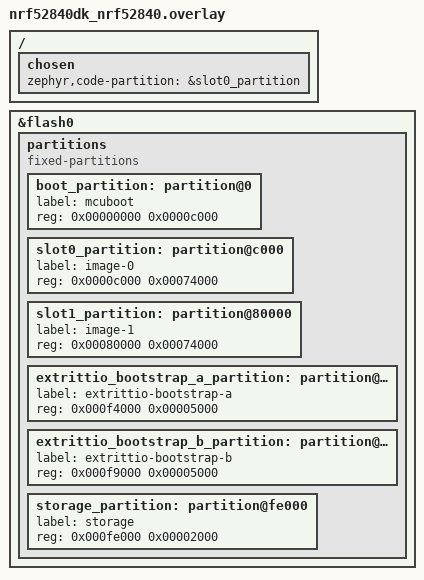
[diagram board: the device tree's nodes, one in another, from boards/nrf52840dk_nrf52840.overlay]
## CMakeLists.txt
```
# Copyright (c) 2026 Extrittio contributors
# SPDX-License-Identifier: Apache-2.0

cmake_minimum_required(VERSION 3.20.0)

list(APPEND ZEPHYR_EXTRA_MODULES
  "${CMAKE_CURRENT_LIST_DIR}/../c/sdk-c"
)
find_package(Zephyr REQUIRED HINTS $ENV{ZEPHYR_BASE})
project(extrittio_zephyr)

# zenoh-pico 1.9.0 contains an mbedTLS transport but its upstream Zephyr glue
# does not expose it. Compile that existing port into the application and make
# the feature visible consistently to both the library and application sources.
zephyr_compile_definitions(ZENOH_GENERIC)
zephyr_include_directories(include)
target_include_directories(zephyr_interface BEFORE INTERFACE
  ${CMAKE_CURRENT_LIST_DIR}/include
)

target_sources(app PRIVATE
  src/main.c
  src/identity.c
  src/provisioning_store.c
  src/ble_provisioning.c
  src/network.c
  src/client.c
  src/ota.c
  src/zenoh_tls.c
  ${ZEPHYR_ZENOH_PICO_MODULE_DIR}/src/runtime/background_executor.c
  ${ZEPHYR_ZENOH_PICO_MODULE_DIR}/src/runtime/executor.c
)

target_include_directories(app PRIVATE
  include
  ../c/sdk-c/include
)
```

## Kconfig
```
# Copyright (c) 2026 Extrittio contributors
# SPDX-License-Identifier: Apache-2.0

menu "Extrittio Zephyr client"

config EXTRITTIO_FACTORY_DEVICE_ID
	string "Factory device identity"
	default ""
	help
	  Stable factory identity presented over BLE and checked against the
	  bootstrap package. Production builds should derive this from protected
	  manufacturing data instead of using this development setting.

config EXTRITTIO_MODEL
	string "Device model"
	default "zephyr-device"

config EXTRITTIO_FIRMWARE_VERSION
	string "Firmware version"
	default "0.1.0"

config EXTRITTIO_PROVISIONING_WINDOW_SECONDS
	int "BLE provisioning window after boot"
	default 300
	range 30 3600
	help
	  A provisioned device advertises the provisioning service after boot only
	  when the board's sw0 button is held. An unprovisioned device always opens
	  this bounded window.

config EXTRITTIO_BOOTSTRAP_BUFFER_SIZE
	int "Bootstrap validation buffer size"
	default 16384
	range 4096 65536

config EXTRITTIO_ZENOH_RETRY_SECONDS
	int "Zenoh reconnect delay"
	default 5
	range 1 300

config EXTRITTIO_OTA_DOWNLOAD_BUFFER_SIZE
	int "OTA HTTP receive buffer"
	default 1024
	range 512 8192

endmenu

source "Kconfig.zephyr"
```

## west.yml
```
manifest:
  version: "1.2"

  projects:
    - name: zephyr
      url: https://github.com/zephyrproject-rtos/zephyr.git
      revision: 1f6485eca25431b5ff27ce9a754218c9e559bbbb # v4.4.1
      import: true
    - name: zenoh-pico
      url: https://github.com/eclipse-zenoh/zenoh-pico.git
      revision: e83d39b4415f6897e8d6c3b3b651ca88a05f4a17 # v1.9.0
      path: modules/lib/zenoh-pico
    - name: cjson
      url: https://github.com/DaveGamble/cJSON.git
      revision: acc76239bee01d8e9c858ae2cab296704e52d916 # v1.7.18
      path: modules/lib/cjson

  self:
    path: extrittio
```

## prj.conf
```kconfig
CONFIG_MAIN_STACK_SIZE=6144
CONFIG_SYSTEM_WORKQUEUE_STACK_SIZE=4096
CONFIG_HEAP_MEM_POOL_SIZE=98304

CONFIG_GPIO=y
CONFIG_FLASH=y
CONFIG_FLASH_MAP=y
CONFIG_STREAM_FLASH=y
CONFIG_SETTINGS=y
CONFIG_SETTINGS_NVS=y
CONFIG_NVS=y
CONFIG_MPU_ALLOW_FLASH_WRITE=y

CONFIG_BT=y
CONFIG_BT_PERIPHERAL=y
CONFIG_BT_SMP=y
CONFIG_BT_BONDABLE=y
CONFIG_BT_SETTINGS=y
CONFIG_BT_GATT_DYNAMIC_DB=y
CONFIG_BT_DEVICE_NAME="Extrittio"
CONFIG_BT_DEVICE_APPEARANCE=0
CONFIG_BT_BUF_ACL_RX_SIZE=251
CONFIG_BT_BUF_ACL_TX_SIZE=251
CONFIG_BT_L2CAP_TX_MTU=247
CONFIG_BT_CTLR_DATA_LENGTH_MAX=251

CONFIG_NETWORKING=y
CONFIG_NET_IPV6=y
CONFIG_NET_TCP=y
CONFIG_NET_SOCKETS=y
CONFIG_OPENTHREAD=y
CONFIG_OPENTHREAD_SHELL=n
CONFIG_OPENTHREAD_MTD=y
CONFIG_OPENTHREAD_FTD=n
CONFIG_OPENTHREAD_JOINER=n
CONFIG_OPENTHREAD_MANUAL_START=y
CONFIG_OPENTHREAD_THREAD_VERSION_1_3=y

CONFIG_MBEDTLS=y
CONFIG_MBEDTLS_ENABLE_HEAP=y
CONFIG_MBEDTLS_HEAP_SIZE=65536
CONFIG_MBEDTLS_ENTROPY_C=y
CONFIG_MBEDTLS_HMAC_DRBG_C=y
CONFIG_MBEDTLS_MD_C=y
CONFIG_PSA_WANT_ALG_SHA_256=y
CONFIG_MBEDTLS_BASE64_C=y
CONFIG_MBEDTLS_PEM_PARSE_C=y
CONFIG_MBEDTLS_PK_PARSE_C=y
CONFIG_MBEDTLS_X509_CRT_PARSE_C=y
CONFIG_MBEDTLS_SSL_PROTO_TLS1_2=y
CONFIG_MBEDTLS_SSL_SERVER_NAME_INDICATION=y
CONFIG_MBEDTLS_KEY_EXCHANGE_ALL_ENABLED=y

CONFIG_BOOTLOADER_MCUBOOT=y
CONFIG_IMG_MANAGER=y
CONFIG_MCUBOOT_IMG_MANAGER=y
CONFIG_IMG_ERASE_PROGRESSIVELY=y
CONFIG_HTTP_CLIENT=y
CONFIG_DNS_RESOLVER=y

CONFIG_NANOPB=y
CONFIG_EXTRITTIO_SDK_C=y
CONFIG_ZENOH_PICO=y
CONFIG_ZENOH_PICO_MULTI_THREAD=y
CONFIG_ZENOH_PICO_PUBLICATION=y
CONFIG_ZENOH_PICO_SUBSCRIPTION=y
CONFIG_ZENOH_PICO_LINK_TCP=y
CONFIG_ZENOH_PICO_LINK_TLS=y
CONFIG_ZENOH_PICO_QUERY=n
CONFIG_ZENOH_PICO_QUERYABLE=n
CONFIG_ZENOH_PICO_SCOUTING=n

CONFIG_LOG=y
CONFIG_LOG_MODE_DEFERRED=y
CONFIG_LOG_DEFAULT_LEVEL=3
```

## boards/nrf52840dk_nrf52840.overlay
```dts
/ {
	chosen {
		zephyr,code-partition = &slot0_partition;
	};
};

&flash0 {
	/delete-node/ partitions;

	partitions {
		compatible = "fixed-partitions";
		#address-cells = <1>;
		#size-cells = <1>;

		boot_partition: partition@0 {
			label = "mcuboot";
			reg = <0x00000000 0x0000c000>;
		};
		slot0_partition: partition@c000 {
			label = "image-0";
			reg = <0x0000c000 0x00074000>;
		};
		slot1_partition: partition@80000 {
			label = "image-1";
			reg = <0x00080000 0x00074000>;
		};
		extrittio_bootstrap_a_partition: partition@f4000 {
			label = "extrittio-bootstrap-a";
			reg = <0x000f4000 0x00005000>;
		};
		extrittio_bootstrap_b_partition: partition@f9000 {
			label = "extrittio-bootstrap-b";
			reg = <0x000f9000 0x00005000>;
		};
		storage_partition: partition@fe000 {
			label = "storage";
			reg = <0x000fe000 0x00002000>;
		};
	};
};
```

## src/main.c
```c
#include <errno.h>
#include <stdbool.h>

#include <zephyr/device.h>
#include <zephyr/devicetree.h>
#include <zephyr/drivers/gpio.h>
#include <zephyr/kernel.h>
#include <zephyr/logging/log.h>
#include <zephyr/dfu/mcuboot.h>

#include <extrittio/bootstrap.h>

#include "extrittio_zephyr/ble_provisioning.h"
#include "extrittio_zephyr/client.h"
#include "extrittio_zephyr/identity.h"
#include "extrittio_zephyr/network.h"
#include "extrittio_zephyr/ota.h"
#include "extrittio_zephyr/provisioning_store.h"

LOG_MODULE_REGISTER(extrittio_main, CONFIG_LOG_DEFAULT_LEVEL);

#if DT_NODE_HAS_STATUS(DT_ALIAS(sw0), okay)
static const struct gpio_dt_spec provisioning_button =
    GPIO_DT_SPEC_GET(DT_ALIAS(sw0), gpios);
#endif

static bool provisioning_button_pressed(void) {
#if DT_NODE_HAS_STATUS(DT_ALIAS(sw0), okay)
    if (!gpio_is_ready_dt(&provisioning_button) ||
        gpio_pin_configure_dt(&provisioning_button, GPIO_INPUT) != 0) {
        return false;
    }
    return gpio_pin_get_dt(&provisioning_button) > 0;
#else
    return false;
#endif
}

static void default_command(const extrittio_command_t *command,
                            void *user_data) {
    ARG_UNUSED(user_data);
    LOG_WRN("No application handler for command %s", command->command);
}

static void default_shadow(const char *device_id, const char *delta_json,
                           int64_t version, void *user_data) {
    ARG_UNUSED(device_id);
    LOG_INF("Received shadow delta version %lld", version);
    extrittio_ota_payload_t update;
    if (extrittio_ota_parse_from_delta(delta_json, &update)) {
        int result = extrittio_zephyr_ota_request(user_data, &update);
        if (result != 0 && result != -EBUSY) {
            LOG_ERR("Could not schedule firmware update: %d", result);
        }
    }
}

int main(void) {
    if (extrittio_identity_init() != 0 ||
        extrittio_provisioning_store_init() != 0 ||
        extrittio_ble_provisioning_init() != 0) {
        LOG_ERR("Extrittio platform initialization failed");
        return -EIO;
    }
    (void)boot_write_img_confirmed();

    bool provisioned = extrittio_provisioning_store_has_bootstrap();
    bool physical_reprovision = provisioned && provisioning_button_pressed();
    if (!provisioned || physical_reprovision) {
        if (extrittio_ble_provisioning_start(physical_reprovision) != 0) {
            LOG_ERR("Could not open BLE provisioning window");
            return -EIO;
        }
        k_sleep(K_SECONDS(CONFIG_EXTRITTIO_PROVISIONING_WINDOW_SECONDS));
        (void)extrittio_ble_provisioning_stop();
        if (!provisioned) {
            LOG_WRN("Provisioning window expired; reboot to try again");
            return -ETIMEDOUT;
        }
    }

    extrittio_bootstrap_t *bootstrap = k_malloc(sizeof(*bootstrap));
    if (bootstrap == NULL) {
        return -ENOMEM;
    }
    int result = extrittio_provisioning_store_load(bootstrap);
    if (result != 0) {
        LOG_ERR("Stored bootstrap is invalid: %d", result);
        k_free(bootstrap);
        return result;
    }
    result = extrittio_network_start(&bootstrap->network);
    if (result != 0) {
        LOG_ERR("Network start failed: %d", result);
        extrittio_bootstrap_clear(bootstrap);
        k_free(bootstrap);
        return result;
    }

    const extrittio_zephyr_client_callbacks_t callbacks = {
        .command = default_command,
        .shadow_delta = default_shadow,
        .user_data = bootstrap,
    };
    result = extrittio_zephyr_client_run(bootstrap, &callbacks);
    extrittio_bootstrap_clear(bootstrap);
    k_free(bootstrap);
    return result;
}
```

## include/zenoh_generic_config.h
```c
#ifndef EXTRITTIO_ZENOH_GENERIC_CONFIG_H
#define EXTRITTIO_ZENOH_GENERIC_CONFIG_H

/* Feature profile for the pinned zenoh-pico 1.9.0 Zephyr client. */
#define Z_FRAG_MAX_SIZE 4096
#define Z_BATCH_UNICAST_SIZE 2048
#define Z_BATCH_MULTICAST_SIZE 2048
#define Z_CONFIG_SOCKET_TIMEOUT 100
#define Z_TRANSPORT_LEASE 10000
#define Z_TRANSPORT_LEASE_EXPIRE_FACTOR 3
#define Z_RUNTIME_MAX_TASKS 8
#define Z_TRANSPORT_ACCEPT_TIMEOUT 1000
#define Z_TRANSPORT_CONNECT_TIMEOUT 10000

#define Z_FEATURE_UNSTABLE_API 0
#define Z_FEATURE_CONNECTIVITY 0
#define Z_FEATURE_MULTI_THREAD 1
#define Z_FEATURE_PUBLICATION 1
#define Z_FEATURE_ADVANCED_PUBLICATION 0
#define Z_FEATURE_SUBSCRIPTION 1
#define Z_FEATURE_ADVANCED_SUBSCRIPTION 0
#define Z_FEATURE_QUERY 0
#define Z_FEATURE_QUERYABLE 0
#define Z_FEATURE_LIVELINESS 0
#define Z_FEATURE_RAWETH_TRANSPORT 0
#define Z_FEATURE_INTEREST 1
#define Z_FEATURE_LINK_TCP 1
#define Z_FEATURE_LINK_BLUETOOTH 0
#define Z_FEATURE_LINK_WS 0
#define Z_FEATURE_LINK_SERIAL 0
#define Z_FEATURE_LINK_SERIAL_USB 0
#define Z_FEATURE_LINK_TLS 1
#define Z_FEATURE_SCOUTING 0
#define Z_FEATURE_LINK_UDP_MULTICAST 0
#define Z_FEATURE_LINK_UDP_UNICAST 0
#define Z_FEATURE_MULTICAST_TRANSPORT 1
#define Z_FEATURE_UNICAST_TRANSPORT 1
#define Z_FEATURE_FRAGMENTATION 1
#define Z_FEATURE_ENCODING_VALUES 1
#define Z_FEATURE_TCP_NODELAY 1
#define Z_FEATURE_LOCAL_SUBSCRIBER 0
#define Z_FEATURE_LOCAL_QUERYABLE 0
#define Z_FEATURE_SESSION_CHECK 1
#define Z_FEATURE_BATCHING 1
#define Z_FEATURE_BATCH_TX_MUTEX 0
#define Z_FEATURE_BATCH_PEER_MUTEX 0
#define Z_FEATURE_MATCHING 1
#define Z_FEATURE_RX_CACHE 0
#define Z_FEATURE_UNICAST_PEER 0
#define Z_FEATURE_AUTO_RECONNECT 0
#define Z_FEATURE_MULTICAST_DECLARATIONS 0
#define Z_FEATURE_PERIODIC_TASKS 0
#define Z_FEATURE_ADMIN_SPACE 0

#endif
```

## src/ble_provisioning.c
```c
#include "extrittio_zephyr/ble_provisioning.h"

#include <errno.h>
#include <stdio.h>
#include <string.h>

#include <zephyr/bluetooth/bluetooth.h>
#include <zephyr/bluetooth/conn.h>
#include <zephyr/bluetooth/gatt.h>
#include <zephyr/bluetooth/uuid.h>
#include <zephyr/kernel.h>
#include <zephyr/logging/log.h>
#include <zephyr/settings/settings.h>
#include <zephyr/sys/reboot.h>

#include <extrittio/provisioning.h>

#include "extrittio_zephyr/identity.h"
#include "extrittio_zephyr/provisioning_store.h"

LOG_MODULE_REGISTER(extrittio_ble, CONFIG_LOG_DEFAULT_LEVEL);

#define EX_UUID(value) BT_UUID_128_ENCODE(value, 0x1a7c, 0x4a21, 0x9f25, 0xe6b17eb89c11)

static struct bt_uuid_128 service_uuid =
    BT_UUID_INIT_128(EX_UUID(0x9d8d0001));
static struct bt_uuid_128 device_id_uuid =
    BT_UUID_INIT_128(EX_UUID(0x9d8d0002));
static struct bt_uuid_128 model_uuid =
    BT_UUID_INIT_128(EX_UUID(0x9d8d0003));
static struct bt_uuid_128 firmware_uuid =
    BT_UUID_INIT_128(EX_UUID(0x9d8d0004));
static struct bt_uuid_128 transport_uuid =
    BT_UUID_INIT_128(EX_UUID(0x9d8d0005));
static struct bt_uuid_128 message_uuid =
    BT_UUID_INIT_128(EX_UUID(0x9d8d0006));
static struct bt_uuid_128 capabilities_uuid =
    BT_UUID_INIT_128(EX_UUID(0x9d8d0007));

static extrittio_provisioning_transfer_t transfer;
static bool provisioning_allowed;
static char capabilities[192];
static struct k_work_delayable reboot_work;

static ssize_t read_text(struct bt_conn *connection,
                         const struct bt_gatt_attr *attribute, void *buffer,
                         uint16_t length, uint16_t offset,
                         const char *value) {
    return bt_gatt_attr_read(connection, attribute, buffer, length, offset,
                             value, strlen(value));
}

static ssize_t read_device_id(struct bt_conn *connection,
                              const struct bt_gatt_attr *attribute,
                              void *buffer, uint16_t length, uint16_t offset) {
    return read_text(connection, attribute, buffer, length, offset,
                     extrittio_factory_device_id());
}

static ssize_t read_model(struct bt_conn *connection,
                          const struct bt_gatt_attr *attribute, void *buffer,
                          uint16_t length, uint16_t offset) {
    return read_text(connection, attribute, buffer, length, offset,
                     extrittio_device_model());
}

static ssize_t read_firmware(struct bt_conn *connection,
                             const struct bt_gatt_attr *attribute,
                             void *buffer, uint16_t length, uint16_t offset) {
    return read_text(connection, attribute, buffer, length, offset,
                     extrittio_firmware_version());
}

static ssize_t read_transport(struct bt_conn *connection,
                              const struct bt_gatt_attr *attribute,
                              void *buffer, uint16_t length, uint16_t offset) {
    return read_text(connection, attribute, buffer, length, offset,
                     "thread+zenoh-mtls");
}

static ssize_t read_capabilities(struct bt_conn *connection,
                                 const struct bt_gatt_attr *attribute,
                                 void *buffer, uint16_t length,
                                 uint16_t offset) {
    return read_text(connection, attribute, buffer, length, offset,
                     capabilities);
}

static void reboot_handler(struct k_work *work) {
    ARG_UNUSED(work);
    sys_reboot(SYS_REBOOT_COLD);
}

static ssize_t write_message(struct bt_conn *connection,
                             const struct bt_gatt_attr *attribute,
                             const void *buffer, uint16_t length,
                             uint16_t offset, uint8_t flags) {
    ARG_UNUSED(connection);
    ARG_UNUSED(attribute);
    ARG_UNUSED(flags);
    if (!provisioning_allowed || offset != 0U) {
        return BT_GATT_ERR(BT_ATT_ERR_WRITE_NOT_PERMITTED);
    }

    extrittio_provisioning_result_t result =
        extrittio_provisioning_transfer_handle(
            &transfer, buffer, length,
            extrittio_provisioning_store_callbacks(), NULL);
    if (result != EXTRITTIO_PROVISIONING_OK) {
        LOG_WRN("Rejected provisioning frame: %d", result);
        return BT_GATT_ERR(BT_ATT_ERR_VALUE_NOT_ALLOWED);
    }
    if (length >= 4U && ((const uint8_t *)buffer)[3] ==
                            EXTRITTIO_PROVISIONING_COMMIT_OPCODE) {
        provisioning_allowed = false;
        (void)k_work_reschedule(&reboot_work, K_SECONDS(1));
    }
    return length;
}

BT_GATT_SERVICE_DEFINE(
    extrittio_service,
    BT_GATT_PRIMARY_SERVICE(&service_uuid),
    BT_GATT_CHARACTERISTIC(&device_id_uuid.uuid, BT_GATT_CHRC_READ,
                           BT_GATT_PERM_READ, read_device_id, NULL, NULL),
    BT_GATT_CHARACTERISTIC(&model_uuid.uuid, BT_GATT_CHRC_READ,
                           BT_GATT_PERM_READ, read_model, NULL, NULL),
    BT_GATT_CHARACTERISTIC(&firmware_uuid.uuid, BT_GATT_CHRC_READ,
                           BT_GATT_PERM_READ, read_firmware, NULL, NULL),
    BT_GATT_CHARACTERISTIC(&transport_uuid.uuid, BT_GATT_CHRC_READ,
                           BT_GATT_PERM_READ, read_transport, NULL, NULL),
    BT_GATT_CHARACTERISTIC(&message_uuid.uuid,
                           BT_GATT_CHRC_WRITE,
                           BT_GATT_PERM_WRITE_ENCRYPT,
                           NULL, write_message, NULL),
    BT_GATT_CHARACTERISTIC(&capabilities_uuid.uuid, BT_GATT_CHRC_READ,
                           BT_GATT_PERM_READ, read_capabilities, NULL, NULL));

static void connected(struct bt_conn *connection, uint8_t error) {
    if (error == 0U) {
        int result = bt_conn_set_security(connection, BT_SECURITY_L2);
        if (result != 0 && result != -EALREADY) {
            LOG_WRN("Could not request encrypted BLE link: %d", result);
        }
    }
}

static void disconnected(struct bt_conn *connection, uint8_t reason) {
    ARG_UNUSED(connection);
    LOG_DBG("BLE disconnected: 0x%02x", reason);
    extrittio_provisioning_transfer_abort(
        &transfer, extrittio_provisioning_store_callbacks(), NULL);
}

BT_CONN_CB_DEFINE(connection_callbacks) = {
    .connected = connected,
    .disconnected = disconnected,
};

static const struct bt_data advertising_data[] = {
    BT_DATA_BYTES(BT_DATA_FLAGS, BT_LE_AD_GENERAL | BT_LE_AD_NO_BREDR),
    BT_DATA_BYTES(BT_DATA_UUID128_ALL, EX_UUID(0x9d8d0001)),
};

static const struct bt_data scan_response[] = {
    BT_DATA(BT_DATA_NAME_COMPLETE, CONFIG_BT_DEVICE_NAME,
            sizeof(CONFIG_BT_DEVICE_NAME) - 1U),
};

int extrittio_ble_provisioning_init(void) {
    int result = bt_enable(NULL);
    if (result != 0) {
        return result;
    }
    (void)settings_load_subtree("bt");
    extrittio_provisioning_transfer_init(
        &transfer, CONFIG_EXTRITTIO_PROVISIONING_MAX_PAYLOAD);
    snprintf(capabilities, sizeof(capabilities),
             "{\"bootstrap\":[3,4],\"network\":[\"thread\"],"
             "\"transport\":[\"zenoh-mtls\"],\"max_payload\":%u}",
             CONFIG_EXTRITTIO_PROVISIONING_MAX_PAYLOAD);
    k_work_init_delayable(&reboot_work, reboot_handler);
    return 0;
}

int extrittio_ble_provisioning_start(bool allow_reprovisioning) {
    if (extrittio_provisioning_store_has_bootstrap() &&
        !allow_reprovisioning) {
        return -EPERM;
    }
    provisioning_allowed = true;
    int result = bt_le_adv_start(BT_LE_ADV_CONN_FAST_1, advertising_data,
                                 ARRAY_SIZE(advertising_data), scan_response,
                                 ARRAY_SIZE(scan_response));
    if (result == 0) {
        LOG_INF("BLE provisioning window opened");
    }
    return result;
}

int extrittio_ble_provisioning_stop(void) {
    provisioning_allowed = false;
    extrittio_provisioning_transfer_abort(
        &transfer, extrittio_provisioning_store_callbacks(), NULL);
    int result = bt_le_adv_stop();
    return result == -EALREADY ? 0 : result;
}
```

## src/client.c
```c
#include "extrittio_zephyr/client.h"

#include <errno.h>
#include <stdio.h>
#include <string.h>

#include <mbedtls/base64.h>
#include <zephyr/kernel.h>
#include <zephyr/logging/log.h>

#include <extrittio/heartbeat.h>
#include <extrittio/shadow.h>
#include <extrittio/time_utils.h>
#include <zenoh-pico.h>

#include "extrittio_zephyr/identity.h"
#include "extrittio_zephyr/network.h"

LOG_MODULE_REGISTER(extrittio_client, CONFIG_LOG_DEFAULT_LEVEL);

struct route_context {
    const char *key;
    extrittio_zephyr_route_cb callback;
    void *user_data;
};

static int base64_copy(const char *input, char **output) {
    size_t input_length = strlen(input);
    size_t capacity = ((input_length + 2U) / 3U) * 4U + 1U;
    char *encoded = k_malloc(capacity);
    if (encoded == NULL) {
        return -ENOMEM;
    }
    size_t written = 0U;
    int result = mbedtls_base64_encode((unsigned char *)encoded, capacity - 1U,
                                       &written,
                                       (const unsigned char *)input,
                                       input_length);
    if (result != 0) {
        k_free(encoded);
        return -EINVAL;
    }
    encoded[written] = '\0';
    *output = encoded;
    return 0;
}

static void route_handler(z_loaned_sample_t *sample, void *argument) {
    struct route_context *context = argument;
    z_owned_slice_t slice;
    if (z_bytes_to_slice(z_sample_payload(sample), &slice) != Z_OK) {
        return;
    }
    const z_loaned_slice_t *loaned = z_slice_loan(&slice);
    context->callback(context->key, z_slice_data(loaned), z_slice_len(loaned),
                      context->user_data);
    z_slice_drop(z_slice_move(&slice));
}

static int configure_tls(z_loaned_config_t *config,
                         const extrittio_bootstrap_t *bootstrap,
                         char **ca, char **certificate, char **private_key) {
    int result = base64_copy(bootstrap->credentials.ca_pem, ca);
    if (result == 0) {
        result = base64_copy(bootstrap->credentials.certificate_pem,
                             certificate);
    }
    if (result == 0) {
        result = base64_copy(bootstrap->credentials.private_key_pem,
                             private_key);
    }
    if (result != 0) {
        return result;
    }

    zp_config_insert(config, Z_CONFIG_TLS_ROOT_CA_CERTIFICATE_BASE64_KEY, *ca);
    zp_config_insert(config, Z_CONFIG_TLS_CONNECT_CERTIFICATE_BASE64_KEY,
                     *certificate);
    zp_config_insert(config, Z_CONFIG_TLS_CONNECT_PRIVATE_KEY_BASE64_KEY,
                     *private_key);
    zp_config_insert(config, Z_CONFIG_TLS_ENABLE_MTLS_KEY, "true");
    zp_config_insert(config, Z_CONFIG_TLS_VERIFY_NAME_ON_CONNECT_KEY, "true");
    return 0;
}

static void clear_secret(char **value) {
    if (*value != NULL) {
        memset(*value, 0, strlen(*value));
        k_free(*value);
        *value = NULL;
    }
}

static int run_session(
    const extrittio_bootstrap_t *bootstrap,
    const extrittio_zephyr_client_callbacks_t *callbacks) {
    z_owned_config_t config;
    z_config_default(&config);
    zp_config_insert(z_loan_mut(config), Z_CONFIG_CONNECT_KEY,
                     bootstrap->contract.zenoh_endpoint);

    char *ca = NULL;
    char *certificate = NULL;
    char *private_key = NULL;
    int result = configure_tls(z_loan_mut(config), bootstrap, &ca,
                               &certificate, &private_key);
    if (result != 0) {
        z_drop(z_move(config));
        goto cleanup_secrets;
    }

    z_owned_session_t session;
    result = z_open(&session, z_move(config), NULL);
    clear_secret(&private_key);
    clear_secret(&certificate);
    clear_secret(&ca);
    if (result != Z_OK) {
        return -ECONNREFUSED;
    }
    if (zp_start_read_task(z_loan_mut(session), NULL) != Z_OK ||
        zp_start_lease_task(z_loan_mut(session), NULL) != Z_OK) {
        z_drop(z_move(session));
        return -EIO;
    }

    z_owned_subscriber_t command_subscriber;
    z_owned_subscriber_t shadow_subscriber;
    bool has_command_subscriber = false;
    bool has_shadow_subscriber = false;
    if (callbacks != NULL && callbacks->command != NULL) {
        has_command_subscriber = extrittio_command_subscribe(
                                     z_loan_mut(session), bootstrap->device_id,
                                     callbacks->command, callbacks->user_data,
                                     &command_subscriber) == 0;
    }
    if (callbacks != NULL && callbacks->shadow_delta != NULL) {
        has_shadow_subscriber = extrittio_shadow_delta_subscribe(
                                    z_loan_mut(session), bootstrap->device_id,
                                    callbacks->shadow_delta,
                                    callbacks->user_data,
                                    &shadow_subscriber) == 0;
    }

    z_owned_subscriber_t route_subscribers[EXTRITTIO_CONTRACT_MAX_ROUTES];
    struct route_context route_contexts[EXTRITTIO_CONTRACT_MAX_ROUTES];
    size_t route_subscriber_count = 0U;
    if (callbacks != NULL && callbacks->route != NULL) {
        for (size_t index = 0; index < bootstrap->contract.route_count; index++) {
            const extrittio_contract_route_t *route =
                &bootstrap->contract.routes[index];
            if (route->direction != EXTRITTIO_ROUTE_CLOUD_TO_DEVICE) {
                continue;
            }
            route_contexts[route_subscriber_count] = (struct route_context){
                .key = route->key,
                .callback = callbacks->route,
                .user_data = callbacks->user_data,
            };
            z_view_keyexpr_t key_expression;
            z_view_keyexpr_from_str(&key_expression, route->address);
            z_owned_closure_sample_t closure;
            z_closure(&closure, route_handler, NULL,
                      &route_contexts[route_subscriber_count]);
            if (z_declare_subscriber(
                    z_loan_mut(session),
                    &route_subscribers[route_subscriber_count],
                    z_loan(key_expression), z_move(closure), NULL) == Z_OK) {
                route_subscriber_count++;
            }
        }
    }

    LOG_INF("Zenoh mTLS connected to %s",
            bootstrap->contract.zenoh_endpoint);
    (void)extrittio_shadow_get_publish(z_loan_mut(session),
                                       bootstrap->device_id);
    uint64_t interval = bootstrap->contract.heartbeat_interval_ms;
    if (interval == 0U) {
        interval = 30000U;
    }
    while (extrittio_network_is_ready()) {
        extrittio_heartbeat_t heartbeat = {
            .device_id = bootstrap->device_id,
            .timestamp = extrittio_now_millis(),
            .status = "online",
            .firmware = extrittio_firmware_version(),
            .uptime_seconds = k_uptime_get() / 1000,
        };
        if (extrittio_heartbeat_publish(z_loan_mut(session), &heartbeat) != 0) {
            result = -EIO;
            break;
        }
        k_sleep(K_MSEC(interval));
    }

    for (size_t index = 0; index < route_subscriber_count; index++) {
        z_drop(z_move(route_subscribers[index]));
    }
    if (has_shadow_subscriber) {
        z_drop(z_move(shadow_subscriber));
    }
    if (has_command_subscriber) {
        z_drop(z_move(command_subscriber));
    }
    z_drop(z_move(session));
    return result;

cleanup_secrets:
    clear_secret(&private_key);
    clear_secret(&certificate);
    clear_secret(&ca);
    return result;
}

int extrittio_zephyr_client_run(
    const extrittio_bootstrap_t *bootstrap,
    const extrittio_zephyr_client_callbacks_t *callbacks) {
    if (bootstrap == NULL ||
        strncmp(bootstrap->contract.zenoh_endpoint, "tls/", 4U) != 0) {
        LOG_ERR("A tls/ Zenoh endpoint is required");
        return -EINVAL;
    }
    while (true) {
        int result = run_session(bootstrap, callbacks);
        LOG_WRN("Zenoh session ended (%d); retrying", result);
        k_sleep(K_SECONDS(CONFIG_EXTRITTIO_ZENOH_RETRY_SECONDS));
    }
}
```

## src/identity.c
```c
#include "extrittio_zephyr/identity.h"

#include <stdio.h>

#include <zephyr/drivers/hwinfo.h>
#include <zephyr/logging/log.h>

LOG_MODULE_REGISTER(extrittio_identity, CONFIG_LOG_DEFAULT_LEVEL);

static char factory_id[129];

int extrittio_identity_init(void) {
    if (CONFIG_EXTRITTIO_FACTORY_DEVICE_ID[0] != '\0') {
        snprintf(factory_id, sizeof(factory_id), "%s",
                 CONFIG_EXTRITTIO_FACTORY_DEVICE_ID);
        return 0;
    }

    uint8_t hardware_id[16];
    ssize_t length = hwinfo_get_device_id(hardware_id, sizeof(hardware_id));
    if (length <= 0) {
        LOG_ERR("No factory identity is configured and hardware ID is unavailable");
        return -1;
    }

    size_t position = 0;
    position += (size_t)snprintf(factory_id, sizeof(factory_id), "zephyr-");
    for (ssize_t index = 0; index < length && position + 2 < sizeof(factory_id);
         index++) {
        position += (size_t)snprintf(factory_id + position,
                                     sizeof(factory_id) - position,
                                     "%02x", hardware_id[index]);
    }
    LOG_INF("Using hardware-derived factory identity %s", factory_id);
    return 0;
}

const char *extrittio_factory_device_id(void) { return factory_id; }

const char *extrittio_device_model(void) { return CONFIG_EXTRITTIO_MODEL; }

const char *extrittio_firmware_version(void) {
    return CONFIG_EXTRITTIO_FIRMWARE_VERSION;
}
```

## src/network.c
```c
#include "extrittio_zephyr/network.h"

#include <errno.h>
#include <string.h>

#include <openthread.h>
#include <openthread/dataset.h>
#include <openthread/ip6.h>
#include <openthread/thread.h>
#include <zephyr/kernel.h>
#include <zephyr/logging/log.h>
#include <zephyr/net/net_if.h>
#include <zephyr/net/openthread.h>

LOG_MODULE_REGISTER(extrittio_network, CONFIG_LOG_DEFAULT_LEVEL);

static bool ready;

static int hex_nibble(char value) {
    if (value >= '0' && value <= '9') {
        return value - '0';
    }
    if (value >= 'a' && value <= 'f') {
        return value - 'a' + 10;
    }
    if (value >= 'A' && value <= 'F') {
        return value - 'A' + 10;
    }
    return -1;
}

static int decode_dataset(const char *hex, otOperationalDatasetTlvs *dataset) {
    size_t length = strlen(hex);
    if (length == 0U || (length & 1U) != 0U ||
        length / 2U > sizeof(dataset->mTlvs)) {
        return -EINVAL;
    }
    dataset->mLength = (uint8_t)(length / 2U);
    for (size_t index = 0; index < dataset->mLength; index++) {
        int upper = hex_nibble(hex[index * 2U]);
        int lower = hex_nibble(hex[index * 2U + 1U]);
        if (upper < 0 || lower < 0) {
            return -EINVAL;
        }
        dataset->mTlvs[index] = (uint8_t)((upper << 4) | lower);
    }
    return 0;
}

static int start_thread(const extrittio_bootstrap_network_t *network) {
    otOperationalDatasetTlvs dataset = {0};
    int result = decode_dataset(network->thread_dataset_hex, &dataset);
    if (result != 0) {
        return result;
    }

    struct openthread_context *context = openthread_get_default_context();
    if (context == NULL) {
        return -ENODEV;
    }
    otInstance *instance = openthread_get_default_instance();
    openthread_mutex_lock();
    otError error = otDatasetSetActiveTlvs(instance, &dataset);
    if (error == OT_ERROR_NONE) {
        error = otIp6SetEnabled(instance, true);
    }
    if (error == OT_ERROR_NONE) {
        error = otThreadSetEnabled(instance, true);
    }
    openthread_mutex_unlock();
    if (error != OT_ERROR_NONE) {
        LOG_ERR("OpenThread start failed: %d", error);
        return -EIO;
    }

    int64_t deadline = k_uptime_get() + 60000;
    while (k_uptime_get() < deadline) {
        openthread_mutex_lock();
        otDeviceRole role = otThreadGetDeviceRole(instance);
        openthread_mutex_unlock();
        if (role == OT_DEVICE_ROLE_CHILD || role == OT_DEVICE_ROLE_ROUTER ||
            role == OT_DEVICE_ROLE_LEADER) {
            ready = true;
            LOG_INF("Attached to Thread network as role %d", role);
            return 0;
        }
        k_sleep(K_MSEC(250));
    }
    return -ETIMEDOUT;
}

static int wait_for_default_interface(void) {
    struct net_if *interface = net_if_get_default();
    if (interface == NULL) {
        return -ENODEV;
    }
    int64_t deadline = k_uptime_get() + 60000;
    while (k_uptime_get() < deadline) {
        if (net_if_is_up(interface) && net_if_is_carrier_ok(interface)) {
            ready = true;
            return 0;
        }
        k_sleep(K_MSEC(250));
    }
    return -ETIMEDOUT;
}

int extrittio_network_start(const extrittio_bootstrap_network_t *network) {
    if (network == NULL) {
        return -EINVAL;
    }
    ready = false;
    switch (network->type) {
    case EXTRITTIO_NETWORK_THREAD:
        return start_thread(network);
    case EXTRITTIO_NETWORK_ETHERNET:
        return wait_for_default_interface();
    case EXTRITTIO_NETWORK_WIFI:
        LOG_ERR("This board build has no Wi-Fi credentials adapter");
        return -ENOTSUP;
    default:
        return -EINVAL;
    }
}

bool extrittio_network_is_ready(void) { return ready; }
```

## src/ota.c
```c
#include "extrittio_zephyr/ota.h"

#include <errno.h>
#include <string.h>

#include <psa/crypto.h>
#include <zephyr/dfu/flash_img.h>
#include <zephyr/dfu/mcuboot.h>
#include <zephyr/kernel.h>
#include <zephyr/logging/log.h>
#include <zephyr/net/http/client.h>
#include <zephyr/net/socket.h>
#include <zephyr/net/tls_credentials.h>
#include <zephyr/posix/netdb.h>
#include <zephyr/posix/sys/socket.h>
#include <zephyr/posix/unistd.h>
#include <zephyr/sys/reboot.h>

LOG_MODULE_REGISTER(extrittio_ota, CONFIG_LOG_DEFAULT_LEVEL);

#define OTA_TLS_TAG 43
#define OTA_WORK_STACK_SIZE 8192

struct ota_download_context {
    struct flash_img_context flash;
    psa_hash_operation_t sha;
    int error;
    bool body_received;
    uint8_t recv_buffer[CONFIG_EXTRITTIO_OTA_DOWNLOAD_BUFFER_SIZE];
};

static struct k_work_q ota_work_queue;
static struct k_work ota_work;
static atomic_t ota_pending;
static bool ota_queue_started;
static const extrittio_bootstrap_t *queued_bootstrap;
static extrittio_ota_payload_t queued_update;
K_THREAD_STACK_DEFINE(ota_work_stack, OTA_WORK_STACK_SIZE);

static int parse_https_url(const char *url, char *host, size_t host_capacity,
                           char *port, size_t port_capacity,
                           const char **path) {
    static const char prefix[] = "https://";
    if (url == NULL || strncmp(url, prefix, sizeof(prefix) - 1U) != 0) {
        return -EPROTONOSUPPORT;
    }

    const char *authority = url + sizeof(prefix) - 1U;
    const char *slash = strchr(authority, '/');
    size_t authority_length = slash == NULL
                                  ? strlen(authority)
                                  : (size_t)(slash - authority);
    const char *colon = memchr(authority, ':', authority_length);
    size_t host_length = colon == NULL
                             ? authority_length
                             : (size_t)(colon - authority);
    if (host_length == 0U || host_length >= host_capacity) {
        return -EINVAL;
    }
    memcpy(host, authority, host_length);
    host[host_length] = '\0';

    const char *port_value = "443";
    size_t port_length = 3U;
    if (colon != NULL) {
        port_value = colon + 1;
        port_length = authority_length - host_length - 1U;
        if (port_length == 0U || port_length >= port_capacity) {
            return -EINVAL;
        }
    }
    memcpy(port, port_value, port_length);
    port[port_length] = '\0';
    *path = slash == NULL ? "/" : slash;
    return 0;
}

static int connect_https(const char *host, const char *port) {
    struct addrinfo hints = {
        .ai_family = AF_UNSPEC,
        .ai_socktype = SOCK_STREAM,
    };
    struct addrinfo *addresses = NULL;
    int result = getaddrinfo(host, port, &hints, &addresses);
    if (result != 0) {
        return -EHOSTUNREACH;
    }

    int socket_fd = -1;
    const sec_tag_t tags[] = {OTA_TLS_TAG};
    for (struct addrinfo *address = addresses; address != NULL;
         address = address->ai_next) {
        socket_fd = socket(address->ai_family, SOCK_STREAM, IPPROTO_TLS_1_2);
        if (socket_fd < 0) {
            continue;
        }
        if (setsockopt(socket_fd, SOL_TLS, TLS_SEC_TAG_LIST, tags,
                       sizeof(tags)) == 0 &&
            setsockopt(socket_fd, SOL_TLS, TLS_HOSTNAME, host,
                       strlen(host) + 1U) == 0 &&
            connect(socket_fd, address->ai_addr, address->ai_addrlen) == 0) {
            break;
        }
        close(socket_fd);
        socket_fd = -1;
    }
    freeaddrinfo(addresses);
    return socket_fd < 0 ? -ECONNREFUSED : socket_fd;
}

static int response_callback(struct http_response *response,
                             enum http_final_call final_data,
                             void *user_data) {
    struct ota_download_context *context = user_data;
    if (response->http_status_code != 200U) {
        context->error = -EBADMSG;
        return context->error;
    }
    if (response->body_frag_len > 0U) {
        context->body_received = true;
        context->error = flash_img_buffered_write(
            &context->flash, response->body_frag_start,
            response->body_frag_len, false);
        if (context->error == 0) {
            psa_status_t status = psa_hash_update(
                &context->sha, response->body_frag_start,
                response->body_frag_len);
            context->error = status == PSA_SUCCESS ? 0 : -EIO;
        }
    }
    if (context->error == 0 && final_data == HTTP_DATA_FINAL) {
        context->error = flash_img_buffered_write(&context->flash, NULL, 0U,
                                                  true);
    }
    return context->error;
}

static int hex_nibble(char value) {
    if (value >= '0' && value <= '9') {
        return value - '0';
    }
    if (value >= 'a' && value <= 'f') {
        return value - 'a' + 10;
    }
    if (value >= 'A' && value <= 'F') {
        return value - 'A' + 10;
    }
    return -1;
}

static int decode_sha256(const char *hex, uint8_t output[32]) {
    if (hex == NULL || strlen(hex) != 64U) {
        return -EINVAL;
    }
    for (size_t index = 0; index < 32U; index++) {
        int upper = hex_nibble(hex[index * 2U]);
        int lower = hex_nibble(hex[index * 2U + 1U]);
        if (upper < 0 || lower < 0) {
            return -EINVAL;
        }
        output[index] = (uint8_t)((upper << 4) | lower);
    }
    return 0;
}

int extrittio_zephyr_ota_install(
    const extrittio_bootstrap_t *bootstrap,
    const extrittio_ota_payload_t *update) {
    if (bootstrap == NULL || update == NULL ||
        bootstrap->credentials.ca_pem[0] == '\0') {
        return -EINVAL;
    }

    char host[128];
    char port[6];
    const char *path;
    int result = parse_https_url(update->firmware_url, host, sizeof(host),
                                 port, sizeof(port), &path);
    uint8_t expected_sha[32];
    if (result == 0) {
        result = decode_sha256(update->sha256, expected_sha);
    }
    if (result != 0) {
        return result;
    }

    result = tls_credential_add(OTA_TLS_TAG, TLS_CREDENTIAL_CA_CERTIFICATE,
                                bootstrap->credentials.ca_pem,
                                strlen(bootstrap->credentials.ca_pem) + 1U);
    if (result != 0 && result != -EEXIST) {
        return result;
    }

    int socket_fd = connect_https(host, port);
    if (socket_fd < 0) {
        (void)tls_credential_delete(OTA_TLS_TAG,
                                    TLS_CREDENTIAL_CA_CERTIFICATE);
        return socket_fd;
    }

    struct ota_download_context context = {0};
    context.sha = (psa_hash_operation_t)PSA_HASH_OPERATION_INIT;
    result = psa_hash_setup(&context.sha, PSA_ALG_SHA_256) == PSA_SUCCESS
                 ? 0
                 : -EIO;
    if (result == 0) {
        result = flash_img_init(&context.flash);
    }
    if (result == 0) {
        struct http_request request = {
            .method = HTTP_GET,
            .url = path,
            .host = host,
            .protocol = "HTTP/1.1",
            .response = response_callback,
            .recv_buf = context.recv_buffer,
            .recv_buf_len = sizeof(context.recv_buffer),
        };
        result = http_client_req(socket_fd, &request, 120000, &context);
        if (result >= 0) {
            result = context.error;
        }
    }
    close(socket_fd);
    (void)tls_credential_delete(OTA_TLS_TAG, TLS_CREDENTIAL_CA_CERTIFICATE);

    uint8_t actual_sha[32];
    if (result == 0 && context.body_received) {
        size_t actual_sha_length = 0U;
        result = psa_hash_finish(&context.sha, actual_sha, sizeof(actual_sha),
                                 &actual_sha_length) == PSA_SUCCESS &&
                         actual_sha_length == sizeof(actual_sha)
                     ? 0
                     : -EIO;
    } else if (result == 0) {
        result = -ENODATA;
    }
    (void)psa_hash_abort(&context.sha);
    if (result == 0 && memcmp(expected_sha, actual_sha,
                              sizeof(expected_sha)) != 0) {
        result = -EBADMSG;
    }
    if (result == 0) {
        result = boot_request_upgrade(0);
    }
    return result;
}

static void ota_worker(struct k_work *work) {
    ARG_UNUSED(work);
    int result = extrittio_zephyr_ota_install(queued_bootstrap,
                                              &queued_update);
    atomic_clear(&ota_pending);
    if (result == 0) {
        sys_reboot(SYS_REBOOT_COLD);
    }
    LOG_ERR("Firmware update failed: %d", result);
}

int extrittio_zephyr_ota_request(
    const extrittio_bootstrap_t *bootstrap,
    const extrittio_ota_payload_t *update) {
    if (bootstrap == NULL || update == NULL) {
        return -EINVAL;
    }
    if (!atomic_cas(&ota_pending, 0, 1)) {
        return -EBUSY;
    }
    if (!ota_queue_started) {
        k_work_queue_start(&ota_work_queue, ota_work_stack,
                           K_THREAD_STACK_SIZEOF(ota_work_stack),
                           K_PRIO_PREEMPT(8), NULL);
        k_work_init(&ota_work, ota_worker);
        ota_queue_started = true;
    }
    queued_bootstrap = bootstrap;
    queued_update = *update;
    int result = k_work_submit_to_queue(&ota_work_queue, &ota_work);
    if (result < 0) {
        atomic_clear(&ota_pending);
        return result;
    }
    return 0;
}
```

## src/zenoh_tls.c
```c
#include "zenoh-pico/system/link/tls.h"

#if Z_FEATURE_LINK_TLS == 1

#include <errno.h>
#include <string.h>
#include <sys/socket.h>
#include <unistd.h>

#include <mbedtls/base64.h>
#include <zephyr/net/socket.h>
#include <zephyr/net/tls_credentials.h>
#include <zephyr/posix/netdb.h>

#include "zenoh-pico/link/config/tls.h"
#include "zenoh-pico/utils/pointers.h"

#define EXTRITTIO_TLS_TAG 42

static z_result_t decode_value(const _z_str_intmap_t *config, uint8_t key,
                               unsigned char **output, size_t *length) {
    const char *encoded = _z_str_intmap_get(config, key);
    if (encoded == NULL) {
        return _Z_ERR_GENERIC;
    }

    size_t required = 0U;
    int result = mbedtls_base64_decode(NULL, 0U, &required,
                                       (const unsigned char *)encoded,
                                       strlen(encoded));
    if (result != MBEDTLS_ERR_BASE64_BUFFER_TOO_SMALL && result != 0) {
        return _Z_ERR_GENERIC;
    }
    unsigned char *decoded = z_malloc(required + 1U);
    if (decoded == NULL) {
        return _Z_ERR_SYSTEM_OUT_OF_MEMORY;
    }
    result = mbedtls_base64_decode(decoded, required, &required,
                                   (const unsigned char *)encoded,
                                   strlen(encoded));
    if (result != 0) {
        z_free(decoded);
        return _Z_ERR_GENERIC;
    }
    decoded[required] = '\0';
    *output = decoded;
    *length = required + 1U;
    return _Z_RES_OK;
}

_z_tls_context_t *_z_tls_context_new(void) {
    _z_tls_context_t *context = z_malloc(sizeof(*context));
    if (context != NULL) {
        memset(context, 0, sizeof(*context));
        context->credential_tag = EXTRITTIO_TLS_TAG;
    }
    return context;
}

void _z_tls_context_free(_z_tls_context_t **context) {
    if (context == NULL || *context == NULL) {
        return;
    }
    (void)tls_credential_delete((*context)->credential_tag,
                                TLS_CREDENTIAL_CA_CERTIFICATE);
    (void)tls_credential_delete((*context)->credential_tag,
                                TLS_CREDENTIAL_SERVER_CERTIFICATE);
    (void)tls_credential_delete((*context)->credential_tag,
                                TLS_CREDENTIAL_PRIVATE_KEY);
    z_free((*context)->private_key);
    z_free((*context)->certificate);
    z_free((*context)->ca);
    z_free(*context);
    *context = NULL;
}

static z_result_t load_credentials(_z_tls_context_t *context,
                                   const _z_str_intmap_t *config) {
    size_t ca_length = 0U;
    size_t certificate_length = 0U;
    size_t private_key_length = 0U;
    if (decode_value(config, TLS_CONFIG_ROOT_CA_CERTIFICATE_BASE64_KEY,
                     &context->ca, &ca_length) != _Z_RES_OK ||
        decode_value(config, TLS_CONFIG_CONNECT_CERTIFICATE_BASE64_KEY,
                     &context->certificate, &certificate_length) != _Z_RES_OK ||
        decode_value(config, TLS_CONFIG_CONNECT_PRIVATE_KEY_BASE64_KEY,
                     &context->private_key, &private_key_length) != _Z_RES_OK) {
        return _Z_ERR_GENERIC;
    }

    if (tls_credential_add(context->credential_tag,
                           TLS_CREDENTIAL_CA_CERTIFICATE,
                           context->ca, ca_length) != 0 ||
        tls_credential_add(context->credential_tag,
                           TLS_CREDENTIAL_SERVER_CERTIFICATE,
                           context->certificate, certificate_length) != 0 ||
        tls_credential_add(context->credential_tag,
                           TLS_CREDENTIAL_PRIVATE_KEY,
                           context->private_key, private_key_length) != 0) {
        return _Z_ERR_GENERIC;
    }
    return _Z_RES_OK;
}

z_result_t _z_open_tls(_z_tls_socket_t *sock,
                       const _z_sys_net_endpoint_t *rep,
                       const char *hostname,
                       const _z_str_intmap_t *config,
                       bool peer_socket) {
    if (sock == NULL || rep == NULL || rep->_iptcp == NULL || hostname == NULL) {
        return _Z_ERR_GENERIC;
    }
    memset(sock, 0, sizeof(*sock));
    sock->_sock._fd = -1;
    sock->_is_peer_socket = peer_socket;
    sock->_tls_ctx = _z_tls_context_new();
    if (sock->_tls_ctx == NULL ||
        load_credentials(sock->_tls_ctx, config) != _Z_RES_OK) {
        _z_tls_context_free(&sock->_tls_ctx);
        return _Z_ERR_GENERIC;
    }

    int fd = socket(rep->_iptcp->ai_family, SOCK_STREAM, IPPROTO_TLS_1_2);
    if (fd < 0) {
        _z_tls_context_free(&sock->_tls_ctx);
        return _Z_ERR_GENERIC;
    }
    sec_tag_t tags[] = {(sec_tag_t)sock->_tls_ctx->credential_tag};
    int verify = TLS_PEER_VERIFY_REQUIRED;
    if (setsockopt(fd, SOL_TLS, TLS_SEC_TAG_LIST, tags, sizeof(tags)) < 0 ||
        setsockopt(fd, SOL_TLS, TLS_PEER_VERIFY, &verify, sizeof(verify)) < 0 ||
        setsockopt(fd, SOL_TLS, TLS_HOSTNAME, hostname,
                   strlen(hostname) + 1U) < 0 ||
        connect(fd, rep->_iptcp->ai_addr, rep->_iptcp->ai_addrlen) < 0) {
        close(fd);
        _z_tls_context_free(&sock->_tls_ctx);
        return _Z_ERR_GENERIC;
    }
    sock->_sock._fd = fd;
    sock->_sock._tls_sock = sock;
    return _Z_RES_OK;
}

z_result_t _z_listen_tls(_z_tls_socket_t *sock, const char *host,
                         const char *port, const _z_str_intmap_t *config) {
    (void)sock;
    (void)host;
    (void)port;
    (void)config;
    return _Z_ERR_GENERIC;
}

z_result_t _z_tls_accept(_z_sys_net_socket_t *socket,
                         const _z_sys_net_socket_t *listen_sock) {
    (void)socket;
    (void)listen_sock;
    return _Z_ERR_GENERIC;
}

void _z_close_tls(_z_tls_socket_t *sock) {
    if (sock == NULL) {
        return;
    }
    if (sock->_sock._fd >= 0) {
        close(sock->_sock._fd);
        sock->_sock._fd = -1;
    }
    _z_tls_context_free(&sock->_tls_ctx);
}

size_t _z_read_tls(const _z_tls_socket_t *sock, uint8_t *ptr, size_t len) {
    ssize_t result = recv(sock->_sock._fd, ptr, len, 0);
    return result < 0 ? SIZE_MAX : (size_t)result;
}

size_t _z_write_tls(const _z_tls_socket_t *sock, const uint8_t *ptr,
                    size_t len) {
    ssize_t result = send(sock->_sock._fd, ptr, len, 0);
    return result < 0 ? SIZE_MAX : (size_t)result;
}

size_t _z_write_all_tls(const _z_tls_socket_t *sock, const uint8_t *ptr,
                        size_t len) {
    size_t written = 0U;
    while (written < len) {
        size_t result = _z_write_tls(sock, ptr + written, len - written);
        if (result == SIZE_MAX || result == 0U) {
            return SIZE_MAX;
        }
        written += result;
    }
    return written;
}

#endif
```
